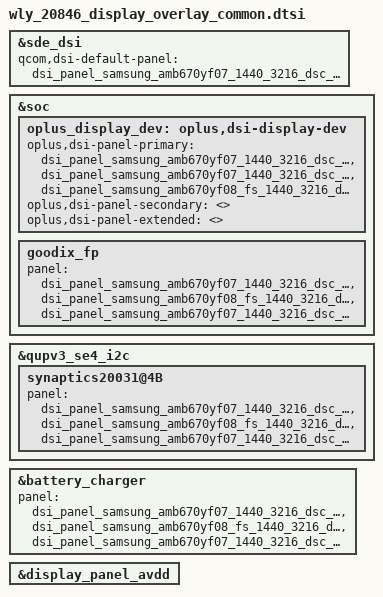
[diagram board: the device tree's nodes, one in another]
#include "../display/dsi-panel-samsung-amb670yf08-fs-1440-3216-dsc-cmd.dtsi"

&sde_dsi {
	qcom,dsi-default-panel = <&dsi_panel_samsung_amb670yf07_1440_3216_dsc_cmd>;
};

&soc {
	oplus_display_dev: oplus,dsi-display-dev {
		oplus,dsi-panel-primary = <
			&dsi_panel_samsung_amb670yf07_1440_3216_dsc_cmd
			&dsi_panel_samsung_amb670yf07_1440_3216_dsc_cmd_t0
			&dsi_panel_samsung_amb670yf08_fs_1440_3216_dsc_cmd
		>;
		oplus,dsi-panel-secondary = <>;
		oplus,dsi-panel-extended = <>;
	};

	goodix_fp {
		panel = <&dsi_panel_samsung_amb670yf07_1440_3216_dsc_cmd
				&dsi_panel_samsung_amb670yf08_fs_1440_3216_dsc_cmd
				&dsi_panel_samsung_amb670yf07_1440_3216_dsc_cmd_t0>;
	};
};

&qupv3_se4_i2c {
	synaptics20031@4B {
		panel = <&dsi_panel_samsung_amb670yf07_1440_3216_dsc_cmd
				&dsi_panel_samsung_amb670yf08_fs_1440_3216_dsc_cmd
				&dsi_panel_samsung_amb670yf07_1440_3216_dsc_cmd_t0>;
	};
};

&battery_charger {
	panel = <&dsi_panel_samsung_amb670yf07_1440_3216_dsc_cmd
			&dsi_panel_samsung_amb670yf08_fs_1440_3216_dsc_cmd
			&dsi_panel_samsung_amb670yf07_1440_3216_dsc_cmd_t0>;
};

&display_panel_avdd {
	/delete-property/ gpio;
	/delete-property/ pinctrl-names;
	/delete-property/ pinctrl-0;
};
